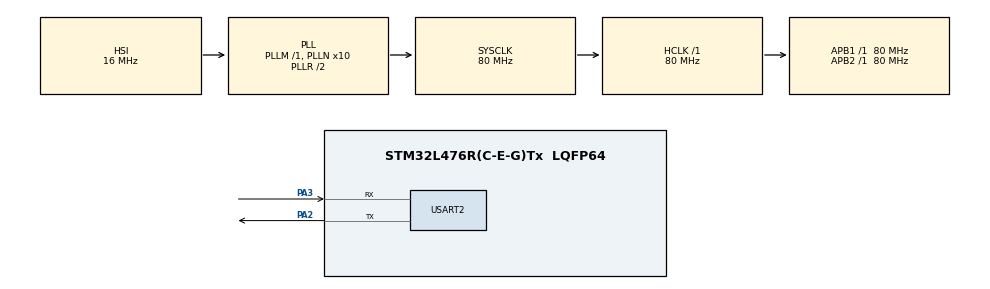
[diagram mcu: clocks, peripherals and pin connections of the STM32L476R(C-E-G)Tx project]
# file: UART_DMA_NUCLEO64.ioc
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Dma.Request0=USART2_RX
Dma.Request1=USART2_TX
Dma.USART2_RX.0.Direction=DMA_PERIPH_TO_MEMORY
Dma.USART2_RX.0.Instance=DMA1_Channel6
Dma.USART2_RX.0.MemDataAlignment=DMA_MDATAALIGN_BYTE
Dma.USART2_RX.0.MemInc=DMA_MINC_ENABLE
Dma.USART2_RX.0.Mode=DMA_NORMAL
Dma.USART2_RX.0.PeriphDataAlignment=DMA_PDATAALIGN_BYTE
Dma.USART2_RX.0.PeriphInc=DMA_PINC_DISABLE
Dma.USART2_RX.0.Priority=DMA_PRIORITY_LOW
Dma.USART2_TX.1.Direction=DMA_MEMORY_TO_PERIPH
Dma.USART2_TX.1.Instance=DMA1_Channel7
Dma.USART2_TX.1.MemDataAlignment=DMA_MDATAALIGN_BYTE
Dma.USART2_TX.1.MemInc=DMA_MINC_ENABLE
Dma.USART2_TX.1.Mode=DMA_NORMAL
Dma.USART2_TX.1.PeriphDataAlignment=DMA_PDATAALIGN_BYTE
Dma.USART2_TX.1.PeriphInc=DMA_PINC_DISABLE
Dma.USART2_TX.1.Priority=DMA_PRIORITY_LOW
Mcu.Family=STM32L4
Mcu.Name=STM32L476R(C-E-G)Tx
Mcu.Package=LQFP64
NVIC.DMA1_Channel6_IRQn=true\:0\:0\:false\:false\:true
NVIC.DMA1_Channel7_IRQn=true\:0\:0\:false\:false\:true
NVIC.PriorityGroup=NVIC_PRIORITYGROUP_4
PA2.Mode=Asynchronous
PA2.Signal=USART2_TX
PA3.Mode=Asynchronous
PA3.Signal=USART2_RX
PH0/OSC_IN.Mode=HSE-External-Oscillator
PH0/OSC_IN.Signal=RCC_OSC_IN
PH1/OSC_OUT.Mode=HSE-External-Oscillator
PH1/OSC_OUT.Signal=RCC_OSC_OUT
ProjectManager.HeapSize=0x200
ProjectManager.StackSize=0x400
ProjectManager.TargetToolchain=EWARM
RCC.ADCFreq_Value=64000000
RCC.AHBFreq_Value=80000000
RCC.APB1Freq_Value=80000000
RCC.APB1TimFreq_Value=80000000
RCC.APB2Freq_Value=80000000
RCC.APB2TimFreq_Value=80000000
RCC.CortexFreq_Value=80000000
RCC.HCLKFreq_Value=80000000
RCC.HSE_VALUE=8000000
RCC.HSI_VALUE=16000000
RCC.LSE_VALUE=32768
RCC.MSI_VALUE=4000000
RCC.PLLN=10
RCC.PLLSourceVirtual=RCC_PLLSOURCE_HSI
RCC.PREFETCH_ENABLE=1
RCC.SYSCLKFreq_VALUE=80000000
RCC.SYSCLKSource=RCC_SYSCLKSOURCE_PLLCLK
RCC.USBFreq_Value=64000000
RCC.VCOOutputFreq_Value=160000000
board=NUCLEO-L476RG

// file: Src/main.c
/**
  ******************************************************************************
  * File Name          : main.c
  * Description        : Main program body
  ******************************************************************************
  *
  * COPYRIGHT(c) 2018 STMicroelectronics
  *
  * Redistribution and use in source and binary forms, with or without modification,
  * are permitted provided that the following conditions are met:
  *   1. Redistributions of source code must retain the above copyright notice,
  *      this list of conditions and the following disclaimer.
  *   2. Redistributions in binary form must reproduce the above copyright notice,
  *      this list of conditions and the following disclaimer in the documentation
  *      and/or other materials provided with the distribution.
  *   3. Neither the name of STMicroelectronics nor the names of its contributors
  *      may be used to endorse or promote products derived from this software
  *      without specific prior written permission.
  *
  * THIS SOFTWARE IS PROVIDED BY THE COPYRIGHT HOLDERS AND CONTRIBUTORS "AS IS"
  * AND ANY EXPRESS OR IMPLIED WARRANTIES, INCLUDING, BUT NOT LIMITED TO, THE
  * IMPLIED WARRANTIES OF MERCHANTABILITY AND FITNESS FOR A PARTICULAR PURPOSE ARE
  * DISCLAIMED. IN NO EVENT SHALL THE COPYRIGHT HOLDER OR CONTRIBUTORS BE LIABLE
  * FOR ANY DIRECT, INDIRECT, INCIDENTAL, SPECIAL, EXEMPLARY, OR CONSEQUENTIAL
  * DAMAGES (INCLUDING, BUT NOT LIMITED TO, PROCUREMENT OF SUBSTITUTE GOODS OR
  * SERVICES; LOSS OF USE, DATA, OR PROFITS; OR BUSINESS INTERRUPTION) HOWEVER
  * CAUSED AND ON ANY THEORY OF LIABILITY, WHETHER IN CONTRACT, STRICT LIABILITY,
  * OR TORT (INCLUDING NEGLIGENCE OR OTHERWISE) ARISING IN ANY WAY OUT OF THE USE
  * OF THIS SOFTWARE, EVEN IF ADVISED OF THE POSSIBILITY OF SUCH DAMAGE.
  *
  ******************************************************************************
  */
#include "stm32l4xx_hal.h"

UART_HandleTypeDef huart2;
DMA_HandleTypeDef hdma_usart2_rx;
DMA_HandleTypeDef hdma_usart2_tx;

/* USER CODE BEGIN PV */
/* Private variables ---------------------------------------------------------*/

/* USER CODE END PV */

void SystemClock_Config(void);
void Error_Handler(void);
static void MX_GPIO_Init(void);
static void MX_DMA_Init(void);
static void MX_USART2_UART_Init(void);

/* USER CODE BEGIN PFP */
/* Private function prototypes -----------------------------------------------*/

/* USER CODE END PFP */

/* USER CODE BEGIN 0 */
uint8_t tx_buff[] = {1,2,3,4,5,6,7,8,9};
uint8_t rx_buff[10] ;
/* USER CODE END 0 */

int main(void)
{

  /* MCU Configuration----------------------------------------------------------*/

  /* Reset of all peripherals, Initializes the Flash interface and the Systick. */
  HAL_Init();

  /* Configure the system clock */
  SystemClock_Config();

  /* Initialize all configured peripherals */
  MX_GPIO_Init();
  MX_DMA_Init();
  MX_USART2_UART_Init();

  /* USER CODE BEGIN 2 */
HAL_UART_Receive_DMA(&huart2,rx_buff,10);
HAL_UART_Transmit_DMA(&huart2,rx_buff,10);
  /* USER CODE END 2 */

  /* Infinite loop */
  while (1)
  {

  }

}

/** System Clock Configuration
*/
void SystemClock_Config(void)
{

  RCC_OscInitTypeDef RCC_OscInitStruct;
  RCC_ClkInitTypeDef RCC_ClkInitStruct;
  RCC_PeriphCLKInitTypeDef PeriphClkInit;

  RCC_OscInitStruct.OscillatorType = RCC_OSCILLATORTYPE_HSI;
  RCC_OscInitStruct.HSIState = RCC_HSI_ON;
  RCC_OscInitStruct.HSICalibrationValue = 16;
  RCC_OscInitStruct.PLL.PLLState = RCC_PLL_ON;
  RCC_OscInitStruct.PLL.PLLSource = RCC_PLLSOURCE_HSI;
  RCC_OscInitStruct.PLL.PLLM = 1;
  RCC_OscInitStruct.PLL.PLLN = 10;
  RCC_OscInitStruct.PLL.PLLP = RCC_PLLP_DIV7;
  RCC_OscInitStruct.PLL.PLLQ = RCC_PLLQ_DIV2;
  RCC_OscInitStruct.PLL.PLLR = RCC_PLLR_DIV2;
  if (HAL_RCC_OscConfig(&RCC_OscInitStruct) != HAL_OK)
  {
    Error_Handler();
  }

  RCC_ClkInitStruct.ClockType = RCC_CLOCKTYPE_HCLK|RCC_CLOCKTYPE_SYSCLK
                              |RCC_CLOCKTYPE_PCLK1|RCC_CLOCKTYPE_PCLK2;
  RCC_ClkInitStruct.SYSCLKSource = RCC_SYSCLKSOURCE_PLLCLK;
  RCC_ClkInitStruct.AHBCLKDivider = RCC_SYSCLK_DIV1;
  RCC_ClkInitStruct.APB1CLKDivider = RCC_HCLK_DIV1;
  RCC_ClkInitStruct.APB2CLKDivider = RCC_HCLK_DIV1;
  if (HAL_RCC_ClockConfig(&RCC_ClkInitStruct, FLASH_LATENCY_4) != HAL_OK)
  {
    Error_Handler();
  }

  PeriphClkInit.PeriphClockSelection = RCC_PERIPHCLK_USART2;
  PeriphClkInit.Usart2ClockSelection = RCC_USART2CLKSOURCE_PCLK1;
  if (HAL_RCCEx_PeriphCLKConfig(&PeriphClkInit) != HAL_OK)
  {
    Error_Handler();
  }

  __HAL_RCC_PWR_CLK_ENABLE();

  if (HAL_PWREx_ControlVoltageScaling(PWR_REGULATOR_VOLTAGE_SCALE1) != HAL_OK)
  {
    Error_Handler();
  }

  HAL_SYSTICK_Config(HAL_RCC_GetHCLKFreq()/1000);

  HAL_SYSTICK_CLKSourceConfig(SYSTICK_CLKSOURCE_HCLK);

  /* SysTick_IRQn interrupt configuration */
  HAL_NVIC_SetPriority(SysTick_IRQn, 0, 0);
}

/* USART2 init function */
static void MX_USART2_UART_Init(void)
{

  huart2.Instance = USART2;
  huart2.Init.BaudRate = 115200;
  huart2.Init.WordLength = UART_WORDLENGTH_7B;
  huart2.Init.StopBits = UART_STOPBITS_1;
  huart2.Init.Parity = UART_PARITY_NONE;
  huart2.Init.Mode = UART_MODE_TX_RX;
  huart2.Init.HwFlowCtl = UART_HWCONTROL_NONE;
  huart2.Init.OverSampling = UART_OVERSAMPLING_16;
  huart2.Init.OneBitSampling = UART_ONE_BIT_SAMPLE_DISABLE;
  huart2.AdvancedInit.AdvFeatureInit = UART_ADVFEATURE_NO_INIT;
  if (HAL_UART_Init(&huart2) != HAL_OK)
  {
    Error_Handler();
  }

}

static void MX_DMA_Init(void)
{
  /* DMA controller clock enable */
  __HAL_RCC_DMA1_CLK_ENABLE();

  /* DMA interrupt init */
  /* DMA1_Channel6_IRQn interrupt configuration */
  HAL_NVIC_SetPriority(DMA1_Channel6_IRQn, 0, 0);
  HAL_NVIC_EnableIRQ(DMA1_Channel6_IRQn);
  /* DMA1_Channel7_IRQn interrupt configuration */
  HAL_NVIC_SetPriority(DMA1_Channel7_IRQn, 0, 0);
  HAL_NVIC_EnableIRQ(DMA1_Channel7_IRQn);

}

/** Configure pins as
        * Analog
        * Input
        * Output
        * EVENT_OUT
        * EXTI
*/
static void MX_GPIO_Init(void)
{

  /* GPIO Ports Clock Enable */
  __HAL_RCC_GPIOH_CLK_ENABLE();
  __HAL_RCC_GPIOA_CLK_ENABLE();

}

/* USER CODE BEGIN 4 */
void HAL_UART_RxCpltCallback(UART_HandleTypeDef *huart){
__NOP();
}
/* USER CODE END 4 */

void Error_Handler(void)
{
  while(1)
  {
  }
}

/************************ (C) COPYRIGHT STMicroelectronics *****END OF FILE****/
